# FM33FK5XX register map
File version: 1.0
CPU: Cortex-M33 r1p0, little endian, MPU, FPU, 3 interrupt priority bits
Registers are 32-bit, read-write, reset 0x0 unless marked. A register's access mark holds for its fields unless they carry their own. Offsets are from the block's base; [hi:lo] are bit positions.

## UART0 — UART0 module information
Base 0x40011C00
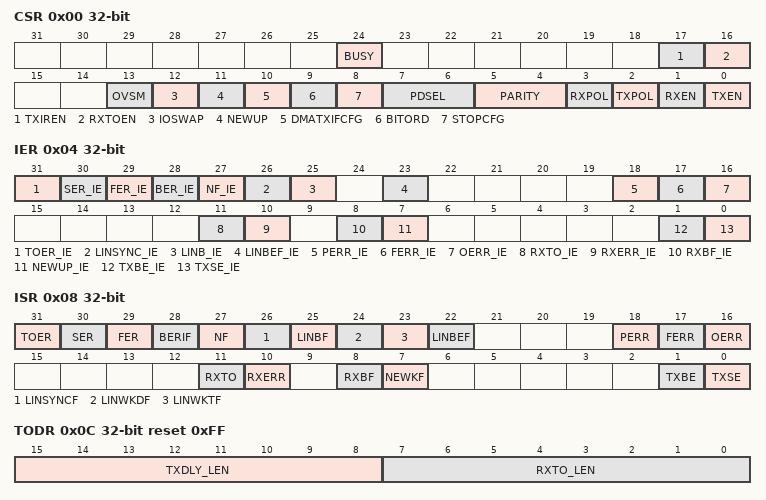
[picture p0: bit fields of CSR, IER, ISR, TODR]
0x00 CSR access per field — UART0ControlStatusRegister
  [24] BUSY ro — BUSY field description
  [17] TXIREN rw — TXIREN field description
  [16] RXTOEN rw — RXTOEN field description
  [13] OVSM rw — OVSM field description
  [12] IOSWAP rw — IOSWAP field description
  [11] NEWUP rw — NEWUP field description
  [10] DMATXIFCFG rw — DMATXIFCFG field description
  [9] BITORD rw — BITORD field description
  [8] STOPCFG rw — STOPCFG field description
  [7:6] PDSEL rw — PDSEL field description
  [5:4] PARITY rw — PARITY field description
  [3] RXPOL rw — RXPOL field description
  [2] TXPOL rw — TXPOL field description
  [1] RXEN rw — RXEN field description
  [0] TXEN rw — TXEN field description
0x04 IER — UART0InterruptEnableRegister
  [31] TOER_IE — TOER_IE field description
  [30] SER_IE — SER_IE field description
  [29] FER_IE — FER_IE field description
  [28] BER_IE — BER_IE field description
  [27] NF_IE — NF_IE field description
  [26] LINSYNC_IE — LINSYNC_IE field description
  [25] LINB_IE — LINB_IE field description
  [23] LINBEF_IE — LINBEF_IE field description
  [18] PERR_IE — PERR_IE field description
  [17] FERR_IE — FERR_IE field description
  [16] OERR_IE — OERR_IE field description
  [11] RXTO_IE — RXTO_IE field description
  [10] RXERR_IE — RXERR_IE field description
  [8] RXBF_IE — RXBF_IE field description
  [7] NEWUP_IE — NEWUP_IE field description
  [1] TXBE_IE — TXBE_IE field description
  [0] TXSE_IE — TXSE_IE field description
0x08 ISR access per field — UART0InterruptStatusRegister
  [31] TOER rw — TOER field description
  [30] SER rw — SER field description
  [29] FER rw — FER field description
  [28] BERIF rw — BERIF field description
  [27] NF rw — NF field description
  [26] LINSYNCF rw — LINSYNCF field description
  [25] LINBF rw — LINBF field description
  [24] LINWKDF rw — LINWKDF field description
  [23] LINWKTF rw — LINWKTF field description
  [22] LINBEF rw — LINBEF field description
  [18] PERR rw — PERR field description
  [17] FERR rw — FERR field description
  [16] OERR rw — OERR field description
  [11] RXTO rw — RXTO field description
  [10] RXERR rw — RXERR field description
  [8] RXBF rw — RXBF field description
  [7] NEWKF rw — NEWKF field description
  [1] TXBE ro — TXBE field description
  [0] TXSE rw — TXSE field description
0x0C TODR reset 0xFF — UART0Time-OutandDelayRegister
  [15:8] TXDLY_LEN — TXDLY_LEN field description
  [7:0] RXTO_LEN — RXTO_LEN field description
0x10 RXBUF ro — UART0ReceiveBuffer
  [8:0] RXBUF — RXBUF field description
0x14 TXBUF wo — UART0TransmitBuffer
  [8:0] TXBUF — TXBUF field description
0x18 BGR reset 0x341 — UART0BaudrateGeneratorRegister
  [15:0] SPBRG — SPBRG field description
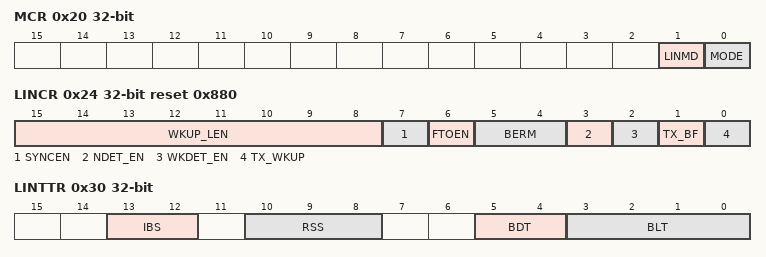
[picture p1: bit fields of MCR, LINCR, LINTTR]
0x20 MCR — UART0ModeControlRegister
  [1] LINMD — LINMD field description
  [0] MODE — MODE field description
0x24 LINCR reset 0x880 — UART0LINControlRegister
  [15:8] WKUP_LEN — WKUP_LEN field description
  [7] SYNCEN — SYNCEN field description
  [6] FTOEN — FTOEN field description
  [5:4] BERM — BERM field description
  [3] NDET_EN — NDET_EN field description
  [2] WKDET_EN — WKDET_EN field description
  [1] TX_BF — TX_BF field description
  [0] TX_WKUP — TX_WKUP field description
0x28 LINBSR ro — UART0LINBaudSyncRegister
  [19:0] BAUD_SYNC — BAUD_SYNC field description
0x2C LINFTR reset 0xFF — UART0LINFrameTimeoutRegister
  [11:0] FTO — FTO field description
0x30 LINTTR — UART0LINTransmitTimingRegister
  [13:12] IBS — IBS field description
  [10:8] RSS — RSS field description
  [5:4] BDT — BDT field description
  [3:0] BLT — BLT field description
0x34 LINPSR ro — UARTLINPre-syncbaudregister
  [19:0] PRE_SYNC — PRE_SYNC field description
0x80 LINSCCR — LINSelf-testCwitchControlRegister
  [1:0] LINSTC — LINSTC field description

## UART1 — UART1 module information
Base 0x40012000
Same registers: UART6 0x40016000, UART7 0x40016400, UART4 0x40016800, UART5 0x40016C00, UART2 0x40017400, UART3 0x40017800
Registers as UART0 (with UART0 read as UART1), without LINSCCR; these are added or differ:
0x34 LINPSR ro — UART1LINPre-syncbaudregister
  [19:0] PRE_SYNC — PRE_SYNC field description
